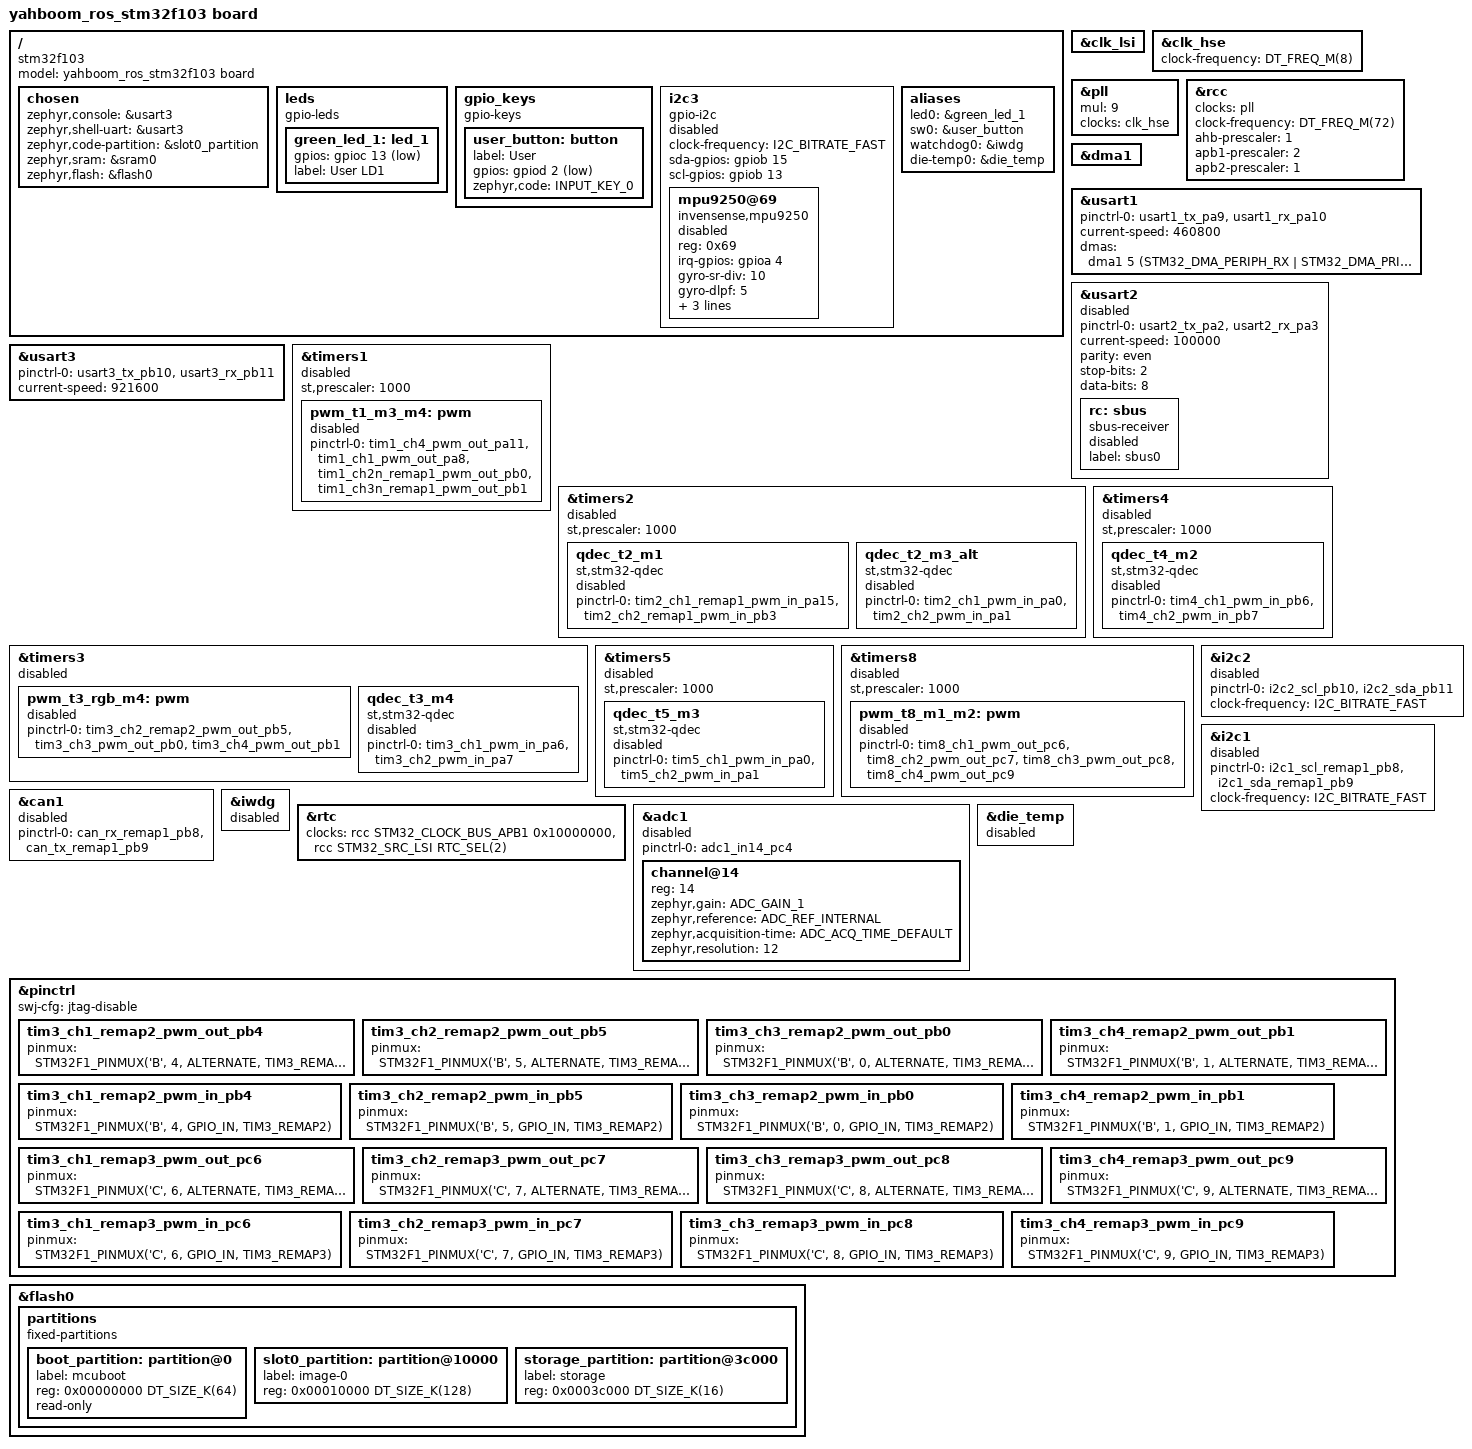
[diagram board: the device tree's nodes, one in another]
/*
 * Copyright (c) 2020 WuhanStudio
 *
 * SPDX-License-Identifier: Apache-2.0
 */

/dts-v1/;
#include <st/f1/stm32f103Xc.dtsi>
#include <st/f1/stm32f103r(c-d-e)tx-pinctrl.dtsi>
#include <zephyr/dt-bindings/input/input-event-codes.h>
#include <zephyr/dt-bindings/dma/stm32_dma.h>

/ {
	model = "yahboom_ros_stm32f103 board";
	compatible = "stm32f103";

	chosen {
		zephyr,console = &usart3;
		zephyr,shell-uart = &usart3;
		zephyr,code-partition = &slot0_partition;
		zephyr,sram = &sram0;
		zephyr,flash = &flash0;
	};

	leds {
		compatible = "gpio-leds";
		green_led_1: led_1 {
			gpios = <&gpioc 13 GPIO_ACTIVE_LOW>;
			label = "User LD1";
		};
	};
	gpio_keys {
		compatible = "gpio-keys";
		user_button: button {
			label = "User";
			gpios = <&gpiod 2 GPIO_ACTIVE_LOW>;
			zephyr,code = <INPUT_KEY_0>;
		};
	};

	/* MPU9250 port*/
	i2c3: i2c3 {
		compatible = "gpio-i2c";
		status = "disabled";
		clock-frequency = <I2C_BITRATE_FAST>;
		sda-gpios = <&gpiob 15 (GPIO_OPEN_DRAIN)>;
		scl-gpios = <&gpiob 13 (GPIO_OPEN_DRAIN)>;
		#address-cells = <1>;
		#size-cells = <0>;

		mpu9250@69 {
				compatible = "invensense,mpu9250";
				reg = <0x69>;
				status = "disabled";
				irq-gpios = <&gpioa 4 GPIO_ACTIVE_HIGH>;
				gyro-sr-div = <10>;
				gyro-dlpf = <5>;
				gyro-fs = <250>;
				accel-fs = <2>;
				accel-dlpf="5.05";
        };
	};

	aliases {
		led0 = &green_led_1;
		sw0 = &user_button;
		watchdog0 = &iwdg;
		die-temp0 = &die_temp;
	};
};

&clk_lsi {
	status = "okay";
};

&clk_hse {
	clock-frequency = <DT_FREQ_M(8)>;
	status = "okay";
};

&pll {
	mul = <9>;
	clocks = <&clk_hse>;
	status = "okay";
};

&rcc {
	clocks = <&pll>;
	clock-frequency = <DT_FREQ_M(72)>;
	ahb-prescaler = <1>;
	apb1-prescaler = <2>;
	apb2-prescaler = <1>;
	/* usbpre not set: USB clock = 72 / 1.5: 48MHz */
};

/* FTDI port */
&dma1 {
	status = "okay";
};

&usart1 {
	pinctrl-0 = <&usart1_tx_pa9 &usart1_rx_pa10>;
	pinctrl-names = "default";
	current-speed = <460800>;
	dmas = <&dma1 5 (STM32_DMA_PERIPH_RX | STM32_DMA_PRIORITY_HIGH)>;
	dma-names = "rx";
	status = "okay";
};

/* SBUS RX only */
&usart2 {
	pinctrl-0 = <&usart2_tx_pa2 &usart2_rx_pa3>;
	pinctrl-names = "default";
	current-speed = <100000>;
	parity = "even";
	stop-bits = "2";
	data-bits = <8>;
	status = "disabled";
    rc: sbus {
        compatible = "sbus-receiver";
        label = "sbus0";
        status = "disabled";
	};
};

/* FTDI or I2C port */
&usart3 {
	/* debug console on PB10/PB11 (shared with i2c2 — keep i2c2 disabled) */
	pinctrl-0 = <&usart3_tx_pb10 &usart3_rx_pb11>;
	pinctrl-names = "default";
	current-speed = <921600>;
	status = "okay";
};

&timers1 {
	st,prescaler = <1000>;
	status = "disabled";

	pwm_t1_m3_m4: pwm {
		status = "disabled";
		pinctrl-0 = <&tim1_ch4_pwm_out_pa11 &tim1_ch1_pwm_out_pa8 &tim1_ch2n_remap1_pwm_out_pb0 &tim1_ch3n_remap1_pwm_out_pb1>;
		pinctrl-names = "default";
	};

};

&timers2 {
	st,prescaler = <1000>;
	status = "disabled";

	qdec_t2_m1 {
		compatible = "st,stm32-qdec";
		status = "disabled";
		pinctrl-0 = <&tim2_ch1_remap1_pwm_in_pa15 &tim2_ch2_remap1_pwm_in_pb3>;
		pinctrl-names = "default";
	};
	qdec_t2_m3_alt {
		compatible = "st,stm32-qdec";
		status = "disabled";
		pinctrl-0 = <&tim2_ch1_pwm_in_pa0 &tim2_ch2_pwm_in_pa1>;
		pinctrl-names = "default";
	};
};

&timers3 {
	status = "disabled";

/* M1 and M2 pwm out */
/*
	pwm_t3_m1_m2_alt: pwm {
		status = "disabled";
		pinctrl-0 = <&tim3_ch1_remap3_pwm_out_pc6 &tim3_ch2_remap3_pwm_out_pc7 &tim3_ch3_remap3_pwm_out_pc8 &tim3_ch4_remap3_pwm_out_pc9>;
		pinctrl-names = "default";
	};
*/
	pwm_t3_rgb_m4: pwm {
        /* RGB pwm out + M4 pwm out */
		status = "disabled";
		pinctrl-0 = <&tim3_ch2_remap2_pwm_out_pb5 &tim3_ch3_pwm_out_pb0 &tim3_ch4_pwm_out_pb1>;
		pinctrl-names = "default";
	};

	qdec_t3_m4 {
        /* M4 qdec input 
          can't use pwm for other 2 pins */
		compatible = "st,stm32-qdec";
		status = "disabled";
		pinctrl-0 = <&tim3_ch1_pwm_in_pa6 &tim3_ch2_pwm_in_pa7>;
		pinctrl-names = "default";
	};
};

&timers4 {
	st,prescaler = <1000>;
	status = "disabled";

	qdec_t4_m2 {
        /* M2 qdec input */
		compatible = "st,stm32-qdec";
		status = "disabled";
		pinctrl-0 = <&tim4_ch1_pwm_in_pb6 &tim4_ch2_pwm_in_pb7>;
		pinctrl-names = "default";
	};
};

&timers5 {
	st,prescaler = <1000>;
	status = "disabled";

	qdec_t5_m3 {
		compatible = "st,stm32-qdec";
		status = "disabled";
		pinctrl-0 = <&tim5_ch1_pwm_in_pa0 &tim5_ch2_pwm_in_pa1>;
		pinctrl-names = "default";
	};
};

&timers8 {
	st,prescaler = <1000>;
	status = "disabled";

	pwm_t8_m1_m2: pwm {
		status = "disabled";
		pinctrl-0 = <&tim8_ch1_pwm_out_pc6 &tim8_ch2_pwm_out_pc7 &tim8_ch3_pwm_out_pc8 &tim8_ch4_pwm_out_pc9>;
		pinctrl-names = "default";
	};
/*
	pwm_t8_m4_alt: pwm {
		status = "disabled";
		pinctrl-0 = <&tim8_ch2n_pwm_out_pb0 &tim8_ch3n_pwm_out_pb1>;
		pinctrl-names = "default";
	};
*/
};

/* OLED i2c port*/
&i2c2 {
	pinctrl-0 = <&i2c2_scl_pb10 &i2c2_sda_pb11>;
	pinctrl-names = "default";
	status = "disabled"; /* PB10/PB11 shared with usart3 (console) */
	clock-frequency = <I2C_BITRATE_FAST>;
};

/* ICM20948 MPU */
/* NOT INSTALLED, see MPU9250 port on i2c3 instead
&spi2 {
	pinctrl-0 = <&spi2_nss_master_pb12 &spi2_sck_master_pb13 &spi2_miso_master_pb14 &spi2_mosi_master_pb15>;
	pinctrl-names = "default";
	status = "disabled";
};
*/

/* on CAN port */
&i2c1 {
    /* disable can1 if i2c1 is enabled */
	pinctrl-0 = <&i2c1_scl_remap1_pb8 &i2c1_sda_remap1_pb9>;
	pinctrl-names = "default";
	clock-frequency = <I2C_BITRATE_FAST>;
	status = "disabled";
};

&can1 {
	/*
        disable i2c1 if can1 is enabled
		pb8 i2c1_scl, tim4_ch3_pwm
		pb9 i2c1_sda, tim4_ch4_pwm
	*/
	pinctrl-0 = <&can_rx_remap1_pb8 &can_tx_remap1_pb9>;
	pinctrl-names = "default";
	status = "disabled";
};

&iwdg {
	status = "disabled";
};

&rtc {
	clocks = <&rcc STM32_CLOCK_BUS_APB1 0x10000000>,
		 <&rcc STM32_SRC_LSI RTC_SEL(2)>;
	status = "okay";
};

&adc1 {
	pinctrl-0 = <&adc1_in14_pc4>;
	pinctrl-names = "default";
	status = "disabled";
	#address-cells = <1>;
	#size-cells = <0>;

	channel@14 {
		reg = <14>;
		zephyr,gain = "ADC_GAIN_1";
		zephyr,reference = "ADC_REF_INTERNAL";
		zephyr,acquisition-time = <ADC_ACQ_TIME_DEFAULT>;
		zephyr,resolution = <12>;
	};

};

&die_temp {
	status = "disabled";
};

&pinctrl {
	/* needed to enable PA15 for T2 encoder */
	swj-cfg = "jtag-disable";

	/* Zephyr v3.5.0 pinctrl dtsi has two TIM3 remap bugs:
	 *
	 * 1. Partial-remap (PB4/PB5/PB0/PB1) nodes are labeled remap1 and use
	 *    TIM3_REMAP1 (reserved). Correct name/value is remap2 / TIM3_REMAP2.
	 *
	 * 2. Full-remap (PC6–PC9) nodes are labeled remap2 and use TIM3_REMAP2
	 *    (partial). Correct name/value is remap3 / TIM3_REMAP3.
	 *
	 * Add the correctly-named nodes and delete the wrong ones so overlays
	 * compile without patching Zephyr. */

	/* partial remap: PB4/PB5/PB0/PB1 — output */
	/omit-if-no-ref/ tim3_ch1_remap2_pwm_out_pb4: tim3_ch1_remap2_pwm_out_pb4 {
		pinmux = <STM32F1_PINMUX('B', 4, ALTERNATE, TIM3_REMAP2)>;
	};
	/omit-if-no-ref/ tim3_ch2_remap2_pwm_out_pb5: tim3_ch2_remap2_pwm_out_pb5 {
		pinmux = <STM32F1_PINMUX('B', 5, ALTERNATE, TIM3_REMAP2)>;
	};
	/omit-if-no-ref/ tim3_ch3_remap2_pwm_out_pb0: tim3_ch3_remap2_pwm_out_pb0 {
		pinmux = <STM32F1_PINMUX('B', 0, ALTERNATE, TIM3_REMAP2)>;
	};
	/omit-if-no-ref/ tim3_ch4_remap2_pwm_out_pb1: tim3_ch4_remap2_pwm_out_pb1 {
		pinmux = <STM32F1_PINMUX('B', 1, ALTERNATE, TIM3_REMAP2)>;
	};
	/* partial remap: PB4/PB5/PB0/PB1 — input */
	/omit-if-no-ref/ tim3_ch1_remap2_pwm_in_pb4: tim3_ch1_remap2_pwm_in_pb4 {
		pinmux = <STM32F1_PINMUX('B', 4, GPIO_IN, TIM3_REMAP2)>;
	};
	/omit-if-no-ref/ tim3_ch2_remap2_pwm_in_pb5: tim3_ch2_remap2_pwm_in_pb5 {
		pinmux = <STM32F1_PINMUX('B', 5, GPIO_IN, TIM3_REMAP2)>;
	};
	/omit-if-no-ref/ tim3_ch3_remap2_pwm_in_pb0: tim3_ch3_remap2_pwm_in_pb0 {
		pinmux = <STM32F1_PINMUX('B', 0, GPIO_IN, TIM3_REMAP2)>;
	};
	/omit-if-no-ref/ tim3_ch4_remap2_pwm_in_pb1: tim3_ch4_remap2_pwm_in_pb1 {
		pinmux = <STM32F1_PINMUX('B', 1, GPIO_IN, TIM3_REMAP2)>;
	};

	/* full remap: PC6/PC7/PC8/PC9 — output */
	/omit-if-no-ref/ tim3_ch1_remap3_pwm_out_pc6: tim3_ch1_remap3_pwm_out_pc6 {
		pinmux = <STM32F1_PINMUX('C', 6, ALTERNATE, TIM3_REMAP3)>;
	};
	/omit-if-no-ref/ tim3_ch2_remap3_pwm_out_pc7: tim3_ch2_remap3_pwm_out_pc7 {
		pinmux = <STM32F1_PINMUX('C', 7, ALTERNATE, TIM3_REMAP3)>;
	};
	/omit-if-no-ref/ tim3_ch3_remap3_pwm_out_pc8: tim3_ch3_remap3_pwm_out_pc8 {
		pinmux = <STM32F1_PINMUX('C', 8, ALTERNATE, TIM3_REMAP3)>;
	};
	/omit-if-no-ref/ tim3_ch4_remap3_pwm_out_pc9: tim3_ch4_remap3_pwm_out_pc9 {
		pinmux = <STM32F1_PINMUX('C', 9, ALTERNATE, TIM3_REMAP3)>;
	};
	/* full remap: PC6/PC7/PC8/PC9 — input */
	/omit-if-no-ref/ tim3_ch1_remap3_pwm_in_pc6: tim3_ch1_remap3_pwm_in_pc6 {
		pinmux = <STM32F1_PINMUX('C', 6, GPIO_IN, TIM3_REMAP3)>;
	};
	/omit-if-no-ref/ tim3_ch2_remap3_pwm_in_pc7: tim3_ch2_remap3_pwm_in_pc7 {
		pinmux = <STM32F1_PINMUX('C', 7, GPIO_IN, TIM3_REMAP3)>;
	};
	/omit-if-no-ref/ tim3_ch3_remap3_pwm_in_pc8: tim3_ch3_remap3_pwm_in_pc8 {
		pinmux = <STM32F1_PINMUX('C', 8, GPIO_IN, TIM3_REMAP3)>;
	};
	/omit-if-no-ref/ tim3_ch4_remap3_pwm_in_pc9: tim3_ch4_remap3_pwm_in_pc9 {
		pinmux = <STM32F1_PINMUX('C', 9, GPIO_IN, TIM3_REMAP3)>;
	};

	/* Delete wrong nodes: TIM3_REMAP1 (reserved) used for PB partial-remap */
	/delete-node/ tim3_ch1_remap1_pwm_out_pb4;
	/delete-node/ tim3_ch2_remap1_pwm_out_pb5;
	/delete-node/ tim3_ch3_remap1_pwm_out_pb0;
	/delete-node/ tim3_ch4_remap1_pwm_out_pb1;
	/delete-node/ tim3_ch1_remap1_pwm_in_pb4;
	/delete-node/ tim3_ch2_remap1_pwm_in_pb5;
	/delete-node/ tim3_ch3_remap1_pwm_in_pb0;
	/delete-node/ tim3_ch4_remap1_pwm_in_pb1;
	/* Delete wrong nodes: TIM3_REMAP2 (partial) used for PC full-remap */
	/delete-node/ tim3_ch1_remap2_pwm_out_pc6;
	/delete-node/ tim3_ch2_remap2_pwm_out_pc7;
	/delete-node/ tim3_ch3_remap2_pwm_out_pc8;
	/delete-node/ tim3_ch4_remap2_pwm_out_pc9;
	/delete-node/ tim3_ch1_remap2_pwm_in_pc6;
	/delete-node/ tim3_ch2_remap2_pwm_in_pc7;
	/delete-node/ tim3_ch3_remap2_pwm_in_pc8;
	/delete-node/ tim3_ch4_remap2_pwm_in_pc9;
};

&flash0 {
        partitions {
                compatible = "fixed-partitions";
                #address-cells = <1>;
                #size-cells = <1>;

                boot_partition: partition@0 {
                        label = "mcuboot";
                        reg = <0x00000000 DT_SIZE_K(64)>;
                        read-only;
                };
                slot0_partition: partition@10000 {
                        label = "image-0";
                        reg = <0x00010000 DT_SIZE_K(128)>;
                };
                /* 16KB storage at the end of 256KB flash (8 x 2KB NVS sectors) */
				storage_partition: partition@3c000 {
					label = "storage";
					reg = <0x0003c000 DT_SIZE_K(16)>;
				};
        };
};



/* for ssd1306_128x32.overlay */
arduino_i2c: &i2c2 {};

